# LargeDummyDevice register map
File version: 1.0
Registers are 32-bit, read-write, no defined reset value unless marked. A register's access mark holds for its fields unless they carry their own. Offsets are from the block's base; [hi:lo] are bit positions.

## PERIPHERAL_40
Base 0x40027000
0x04 REG_1 — Register 1
  [34:31] FIELD_23, [31:30] FIELD_11, [32:29] FIELD_4, [32:29] FIELD_12, [30:29] FIELD_26, [25:24] FIELD_6, [27:23] FIELD_8, [26:23] FIELD_20, [22] FIELD_31, [24:21] FIELD_7, [24:21] FIELD_14, [25:21] FIELD_25, [22:20] FIELD_24, [17:16] FIELD_5, [14] FIELD_10, [17:13] FIELD_2, [14:12] FIELD_21, [15:11] FIELD_27, [13:10] FIELD_16, [13:10] FIELD_18, [11:10] FIELD_19, [12:8] FIELD_30, [9:6] FIELD_3, [6] FIELD_22, [10:6] FIELD_29, [7:5] FIELD_28, [6:4] FIELD_1, [3:2] FIELD_9, [5:2] FIELD_17, [4:0] FIELD_13, [1:0] FIELD_15
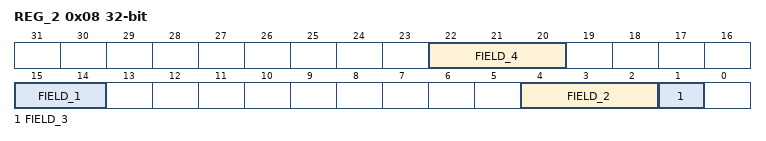
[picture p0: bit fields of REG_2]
0x08 REG_2 — Register 2
  [22:20] FIELD_4, [15:14] FIELD_1, [4:2] FIELD_2, [1] FIELD_3
0x0C REG_3 — Register 3
  [27] FIELD_3, [31:27] FIELD_13, [27:26] FIELD_20, [25] FIELD_14, [27:24] FIELD_8, [24:23] FIELD_12, [24:23] FIELD_17, [20:19] FIELD_4, [18] FIELD_16, [22:18] FIELD_21, [15:14] FIELD_1, [16:14] FIELD_2, [16:13] FIELD_10, [15:13] FIELD_11, [11] FIELD_15, [12:10] FIELD_6, [11:10] FIELD_9, [10] FIELD_19, [11:8] FIELD_7, [9:5] FIELD_22, [5:4] FIELD_18, [4:0] FIELD_5
0x10 REG_4 — Register 4
  [35:31] FIELD_17, [30] FIELD_18, [29] FIELD_15, [31:28] FIELD_9, [32:28] FIELD_21, [27:26] FIELD_1, [29:26] FIELD_23, [25:24] FIELD_2, [24] FIELD_10, [27:24] FIELD_25, [23] FIELD_27, [23:22] FIELD_12, [23:22] FIELD_22, [25:21] FIELD_8, [25:21] FIELD_19, [19:18] FIELD_14, [19:16] FIELD_13, [18:16] FIELD_28, [16:15] FIELD_7, [17:14] FIELD_6, [15:14] FIELD_24, [15:12] FIELD_26, [14:10] FIELD_3, [12:10] FIELD_4, [9:8] FIELD_11, [9:7] FIELD_20, [4] FIELD_5, [0] FIELD_16
0x14 REG_5 — Register 5
  [33:31] FIELD_19, [34:30] FIELD_1, [33:30] FIELD_3, [31:29] FIELD_11, [28:25] FIELD_5, [29:25] FIELD_7, [27:23] FIELD_4, [26:23] FIELD_15, [25:22] FIELD_6, [22:21] FIELD_17, [19] FIELD_14, [19:17] FIELD_12, [17] FIELD_16, [18:14] FIELD_9, [17:14] FIELD_18, [13] FIELD_10, [10] FIELD_2, [10] FIELD_13, [11:9] FIELD_8, [8:5] FIELD_20
0x18 REG_6 — Register 6
  [33:31] FIELD_3, [33:30] FIELD_8, [33:30] FIELD_16, [30:29] FIELD_5, [27:23] FIELD_13, [23:20] FIELD_4, [21:18] FIELD_10, [18:16] FIELD_15, [18:16] FIELD_17, [15] FIELD_6, [15:14] FIELD_7, [13] FIELD_1, [16:12] FIELD_2, [16:12] FIELD_19, [14:11] FIELD_12, [9] FIELD_22, [10:8] FIELD_20, [9:7] FIELD_9, [9:6] FIELD_21, [5] FIELD_14, [3:1] FIELD_23, [4:0] FIELD_11, [0] FIELD_18
0x1C REG_7 — Register 7
  [31] FIELD_6, [35:31] FIELD_9, [29:26] FIELD_5, [28:24] FIELD_1, [27:24] FIELD_13, [27:23] FIELD_15, [19] FIELD_7, [17] FIELD_4, [15] FIELD_10, [12:11] FIELD_8, [12:11] FIELD_14, [11:10] FIELD_2, [8:7] FIELD_16, [8:6] FIELD_12, [3] FIELD_3, [6:3] FIELD_11
0x20 REG_8 — Register 8
  [32:31] FIELD_15, [31:28] FIELD_18, [27] FIELD_14, [27:26] FIELD_13, [25] FIELD_11, [27:25] FIELD_17, [26:24] FIELD_1, [24] FIELD_2, [26:22] FIELD_24, [21:20] FIELD_10, [19:18] FIELD_6, [18:17] FIELD_5, [16] FIELD_3, [16:14] FIELD_28, [14:11] FIELD_19, [12:11] FIELD_27, [14:11] FIELD_29, [12:9] FIELD_7, [13:9] FIELD_26, [12:8] FIELD_4, [10:7] FIELD_23, [7:6] FIELD_25, [7:5] FIELD_9, [5] FIELD_22, [4] FIELD_20, [7:3] FIELD_16, [4:3] FIELD_21, [4:2] FIELD_8, [1:0] FIELD_12
0x24 REG_9 — Register 9
  [29] FIELD_11, [31:28] FIELD_3, [27] FIELD_2, [28:24] FIELD_13, [24:22] FIELD_6, [20] FIELD_12, [18] FIELD_14, [16] FIELD_9, [17:13] FIELD_5, [15:13] FIELD_8, [13:10] FIELD_10, [6] FIELD_1, [8:4] FIELD_7, [4:3] FIELD_4
0x28 REG_10 — Register 10
  [31] FIELD_30, [32:30] FIELD_28, [29] FIELD_25, [31:27] FIELD_3, [29:25] FIELD_17, [27:25] FIELD_20, [24:23] FIELD_16, [23:20] FIELD_1, [20] FIELD_13, [22:19] FIELD_6, [21:19] FIELD_10, [21:19] FIELD_24, [17] FIELD_15, [17:16] FIELD_4, [17:16] FIELD_7, [17:16] FIELD_11, [18:16] FIELD_26, [17:14] FIELD_19, [17:13] FIELD_2, [11:9] FIELD_14, [9:8] FIELD_8, [8] FIELD_22, [8:7] FIELD_18, [10:6] FIELD_5, [8:6] FIELD_12, [6:2] FIELD_21, [1] FIELD_23, [1] FIELD_27, [5:1] FIELD_29, [3:0] FIELD_9
0x2C REG_11 — Register 11
  [33:30] FIELD_1, [31:29] FIELD_4, [29] FIELD_18, [29:26] FIELD_14, [22] FIELD_6, [23:22] FIELD_15, [23:21] FIELD_8, [19:18] FIELD_2, [20:18] FIELD_7, [19:18] FIELD_12, [20:18] FIELD_20, [16] FIELD_9, [17:16] FIELD_13, [19:16] FIELD_22, [16:14] FIELD_19, [16:13] FIELD_3, [16:13] FIELD_10, [15:12] FIELD_5, [12:8] FIELD_11, [8:7] FIELD_16, [11:7] FIELD_21, [3:0] FIELD_17
0x30 REG_12 — Register 12
  [29:28] FIELD_2, [22] FIELD_3, [18:15] FIELD_1, [16:14] FIELD_6, [13] FIELD_5, [8:6] FIELD_4, [7:5] FIELD_7
0x34 REG_13 — Register 13
  [34:30] FIELD_2, [33:29] FIELD_9, [28:27] FIELD_6, [27:23] FIELD_4, [23:21] FIELD_1, [16] FIELD_3, [18:16] FIELD_10, [18:15] FIELD_8, [16:14] FIELD_15, [12:11] FIELD_5, [12:11] FIELD_7, [15:11] FIELD_11, [10:9] FIELD_12, [9:8] FIELD_16, [9:5] FIELD_13, [3:2] FIELD_14
0x38 REG_14 — Register 14
  [33:31] FIELD_18, [30:29] FIELD_8, [32:29] FIELD_12, [27] FIELD_16, [25] FIELD_3, [29:25] FIELD_17, [24:23] FIELD_10, [20:18] FIELD_1, [18] FIELD_11, [19:17] FIELD_6, [17] FIELD_14, [17:14] FIELD_9, [12] FIELD_4, [14:11] FIELD_2, [11:10] FIELD_15, [13:9] FIELD_5, [13:9] FIELD_7, [8] FIELD_13
0x3C REG_15 — Register 15
  [31:30] FIELD_8, [30:28] FIELD_4, [28] FIELD_9, [31:28] FIELD_12, [29:27] FIELD_26, [26:25] FIELD_11, [21] FIELD_1, [21:20] FIELD_28, [21:19] FIELD_6, [23:19] FIELD_7, [20:19] FIELD_22, [20:18] FIELD_5, [20:18] FIELD_14, [22:18] FIELD_27, [18:17] FIELD_3, [20:16] FIELD_18, [19:16] FIELD_29, [19:15] FIELD_31, [18:14] FIELD_15, [14:10] FIELD_2, [9:8] FIELD_16, [9:8] FIELD_17, [9:7] FIELD_24, [9:5] FIELD_13, [9:5] FIELD_23, [8:4] FIELD_10, [3] FIELD_25, [5:2] FIELD_20, [2] FIELD_30, [1] FIELD_21, [1:0] FIELD_19
0x40 REG_16 — Register 16
  [34:31] FIELD_3, [29:27] FIELD_7, [28:26] FIELD_2, [28:24] FIELD_6, [26:23] FIELD_5, [22:19] FIELD_4, [15:14] FIELD_9, [13] FIELD_1, [17:13] FIELD_10, [15:12] FIELD_8
0x44 REG_17 — Register 17
  [18:15] FIELD_2, [11] FIELD_1, [14:11] FIELD_3, [4:2] FIELD_4
